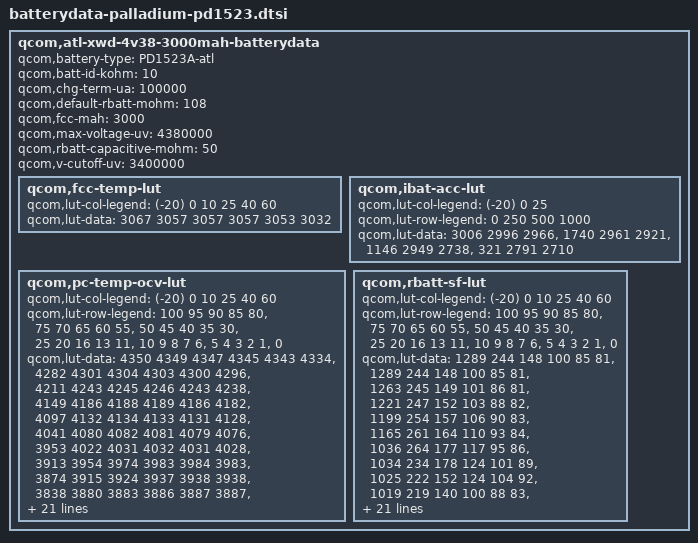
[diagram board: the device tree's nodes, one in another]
/* Copyright (c) 2013-2014, The Linux Foundation. All rights reserved.
 *
 * This program is free software; you can redistribute it and/or modify
 * it under the terms of the GNU General Public License version 2 and
 * only version 2 as published by the Free Software Foundation.
 *
 * This program is distributed in the hope that it will be useful,
 * but WITHOUT ANY WARRANTY; without even the implied warranty of
 * MERCHANTABILITY or FITNESS FOR A PARTICULAR PURPOSE.  See the
 * GNU General Public License for more details.
 */
qcom,atl-xwd-4v38-3000mah-batterydata {
	qcom,battery-type = "PD1523A-atl";
	qcom,batt-id-kohm = <10>;
	qcom,chg-term-ua = <100000>;
	qcom,default-rbatt-mohm = <108>;
	qcom,fcc-mah = <3000>;
	qcom,max-voltage-uv = <4380000>;
	qcom,rbatt-capacitive-mohm = <50>;
	qcom,v-cutoff-uv = <3400000>;

	qcom,fcc-temp-lut {
		qcom,lut-col-legend = <(-20) 0 10 25 40 60>;
		qcom,lut-data = <3067 3057 3057 3057 3053 3032>;
	};

	qcom,ibat-acc-lut {
		qcom,lut-col-legend = <(-20) 0 25>;
		qcom,lut-row-legend = <0 250 500 1000>;
		qcom,lut-data = <3006 2996 2966>,
				<1740 2961 2921>,
				<1146 2949 2738>,
				<321 2791 2710>;
	};

	qcom,pc-temp-ocv-lut {
		qcom,lut-col-legend = <(-20) 0 10 25 40 60>;
		qcom,lut-row-legend = <100 95 90 85 80>,
					<75 70 65 60 55>,
					<50 45 40 35 30>,
					<25 20 16 13 11>,
					<10 9 8 7 6>,
					<5 4 3 2 1>,
					<0>;
		qcom,lut-data = <4350 4349 4347 4345 4343 4334>,
				<4282 4301 4304 4303 4300 4296>,
				<4211 4243 4245 4246 4243 4238>,
				<4149 4186 4188 4189 4186 4182>,
				<4097 4132 4134 4133 4131 4128>,
				<4041 4080 4082 4081 4079 4076>,
				<3953 4022 4031 4032 4031 4028>,
				<3913 3954 3974 3983 3984 3983>,
				<3874 3915 3924 3937 3938 3938>,
				<3838 3880 3883 3886 3887 3887>,
				<3817 3849 3852 3855 3855 3855>,
				<3801 3824 3827 3830 3831 3830>,
				<3787 3803 3807 3809 3810 3809>,
				<3774 3786 3790 3792 3793 3791>,
				<3761 3774 3776 3775 3773 3768>,
				<3746 3762 3762 3757 3749 3738>,
				<3730 3744 3744 3737 3728 3715>,
				<3716 3724 3723 3716 3707 3694>,
				<3702 3706 3702 3696 3687 3677>,
				<3691 3699 3696 3691 3684 3673>,
				<3684 3696 3695 3690 3683 3671>,
				<3677 3694 3693 3688 3682 3669>,
				<3668 3690 3690 3686 3679 3666>,
				<3656 3685 3686 3680 3674 3657>,
				<3639 3671 3671 3663 3652 3634>,
				<3611 3639 3637 3627 3614 3596>,
				<3573 3591 3588 3578 3564 3547>,
				<3519 3528 3524 3515 3501 3485>,
				<3438 3442 3439 3430 3415 3401>,
				<3308 3306 3307 3297 3278 3272>,
				<3000 3000 3000 3000 3000 3000>;
	};

	qcom,rbatt-sf-lut {
		qcom,lut-col-legend = <(-20) 0 10 25 40 60>;
		qcom,lut-row-legend = <100 95 90 85 80>,
					<75 70 65 60 55>,
					<50 45 40 35 30>,
					<25 20 16 13 11>,
					<10 9 8 7 6>,
					<5 4 3 2 1>,
					<0>;
		qcom,lut-data = <1289 244 148 100 85 81>,
				<1289 244 148 100 85 81>,
				<1263 245 149 101 86 81>,
				<1221 247 152 103 88 82>,
				<1199 254 157 106 90 83>,
				<1165 261 164 110 93 84>,
				<1036 264 177 117 95 86>,
				<1034 234 178 124 101 89>,
				<1025 222 152 124 104 92>,
				<1019 219 140 100 88 83>,
				<1057 218 139 99 85 82>,
				<1104 221 141 100 87 82>,
				<1159 224 145 103 90 84>,
				<1228 227 147 105 92 85>,
				<1312 237 149 104 90 84>,
				<1406 250 151 101 86 82>,
				<1510 261 152 100 86 82>,
				<1588 276 155 103 87 82>,
				<1602 282 155 100 85 81>,
				<1555 274 153 101 87 82>,
				<1604 288 156 103 88 83>,
				<1657 295 161 105 90 84>,
				<1714 316 167 108 93 87>,
				<1776 334 174 109 94 86>,
				<1845 348 177 109 89 83>,
				<1998 357 171 106 89 84>,
				<2338 384 180 107 90 85>,
				<2870 421 188 111 94 86>,
				<3756 498 205 118 99 91>,
				<5517 647 267 153 129 107>,
				<11032 1294 534 307 258 214>;
	};
};
